# STM32MP23_CM33 register map
File version: 1.2
CPU: CM33 r0p1, little endian, MPU, FPU, vendor SysTick, 8 interrupt priority bits
Registers are 32-bit, read-write, reset 0x0 unless marked. A register's access mark holds for its fields unless they carry their own. Offsets are from the block's base; [hi:lo] are bit positions; {n}, {i} and the like mark numbered series; 'fields as' and 'values as' point back to an identical list.

## SERC — SERC register block
Base 0x44080000
Same registers: SERC_S 0x54080000
{0x0+4i} SERC_IER{i} (i=0..5) — SERC interrupt enable register {i}
  [31:0] PDRIE — Power-down or reset interrupt enable for peripheral y Sets the bit to unmask access to power-down or reset events from the peripheral y.
    0=power-down or reset access event from peripheral y does not generate an interrupt (masked); 1=power-down or reset access event from peripheral y generates an interrupt (unmasked)
{0x40+4i} SERC_ISR{i} ro (i=0..4) — SERC interrupt status register {i}
  [31:0] PDRS — Power-down or reset interrupt status for peripheral y The collector sets this bit when a bus_ilac is collected for peripheral y.
    0=no power-down or reset event recorded for this peripheral; 1=a power-down or reset access event has been reported from this peripheral
0x54 SERC_ISR5 ro — SERC interrupt status register 5
  [31:0] PDRS — Power-down or reset clear flag for peripheral y The collector sets this bit when a bus_ilac is collected for peripheral y.
    values as SERC_ISR0.PDRS
{0x80+4i} SERC_ICR{i} wo (i=0..5) — SERC interrupt clear register {i}
  [31:0] PDRC — Power-down or reset clear flag for peripheral y When set, this write-only bit clears the status flag of the illegal access event y set in SERC_ISR{i} register.
    0=PDRCy flag status is not affected; 1=PDRCy flag status is cleared in SERC_ISR{i} register
0x100 SERC_ENABLE
  [0] SERFEN — Enable the SERF framework. When the SERF is enabled, an access to a target under reset or clocked off is detected; a functional error response is given back on the IP bus, an illegal access is reported to the SERC, and an interrupt is fired according to the SERC registers configuration. When the SERF is disabled, an access to a target under reset or clocked off is not detected.
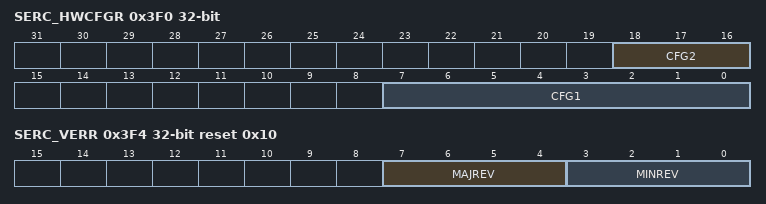
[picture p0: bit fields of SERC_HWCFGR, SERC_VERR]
0x3F0 SERC_HWCFGR ro (reset mask 0xFFF0FF00) — SERC hardware configuration register
  [18:16] CFG2 — NUM_RESYNC_FLOPS, number of resynchronization flops when receiving a bus_ilac information in the SERC clock domain.
  [7:0] CFG1 — NUM_ILAC, number of illegal accesses input pins configured for this instance of the collector.
0x3F4 SERC_VERR ro reset 0x10 — SERC version register
  [7:4] MAJREV — Major revision
  [3:0] MINREV — Minor revision
0x3F8 SERC_IPIDR ro reset 0x1001F0 — SERC identification register
  [31:0] ID — IP identification code
0x3FC SERC_SIDR ro reset 0xA3C5DD01 — SERC size identification register
  [31:0] SID — Size identification code (1 Kbyte)

## STGENR — System timer generator
Base 0x58070000
Same registers: STGENR_S 0x48070000
0x00 STGENR_CNTCVL ro — STGENR value lower register
  [31:0] CNTCVL_L_32 — current value of the timestamp counter (the lower 32 bits)
0x04 STGENR_CNTCVU ro — STGENR value upper register
  [31:0] CNTCVU_U_32 — current value of the timestamp counter (the upper 32 bits)
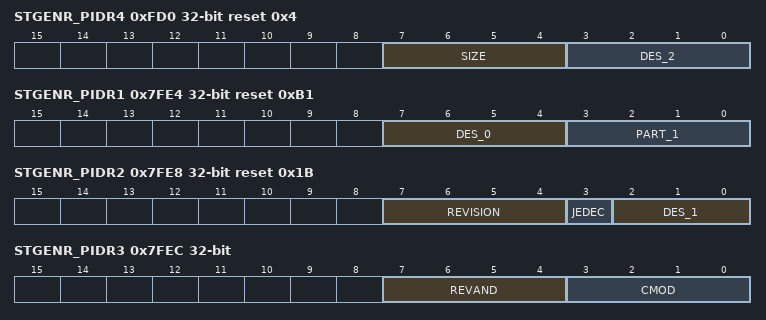
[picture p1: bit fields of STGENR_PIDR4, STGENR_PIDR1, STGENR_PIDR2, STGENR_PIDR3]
0xFD0 STGENR_PIDR4 ro reset 0x4 — STGENR peripheral ID4 register
  [7:4] SIZE — always 0b0000 Indicates that the device only occupies 4 Kbytes of memory.
  [3:0] DES_2 — part of designer identification Together STGEN_PIDR1.DES_0, STGEN_PIDR2.DES_1, and STGEN_PIDR4.DES_2 identify the designer of the component.
{0xFC0+4i} STGENR_PIDR{i} ro (i=5..7) — STGENR peripheral ID{i} register
  [31:0] PIDR{i} — peripheral ID{i}
0x7FE0 STGENR_PIDR0 ro reset 0x1 — STGENR peripheral ID0 register
  [7:0] PART_0 — bits[7:0] of the 12-bit part number of the component.
0x7FE4 STGENR_PIDR1 ro reset 0xB1 — STGENR peripheral ID1 register
  [7:4] DES_0 — part of designer identification Together STGEN_PIDR1.DES_0, STGEN_PIDR2.DES_1, and STGEN_PIDR4.DES_2 identify the designer of the component.
  [3:0] PART_1 — Bits[11:8] of the 12-bit part number of the component
0x7FE8 STGENR_PIDR2 ro reset 0x1B — STGENR peripheral ID2 register
  [7:4] REVISION — device revision number
  [3] JEDEC — always 1 Indicates that the JEDEC-assigned designer ID is used.
  [2:0] DES_1 — part of designer identification Together STGEN_PIDR1.DES_0, STGEN_PIDR2.DES_1, and STGEN_PIDR4.DES_2, identify the designer of the component.
0x7FEC STGENR_PIDR3 ro — STGENR peripheral ID3 register
  [7:4] REVAND — errata fix identification 0b0000 indicates there are no errata fixes to this component.
  [3:0] CMOD — customer modified Indicates whether the customer has modified the behavior of the component. In most cases, this field is 0b0000 (no modification done). Customers change this value when they make authorized modifications to this component.
0x7FF0 STGENR_CIDR0 ro reset 0xD — STGENR component ID0 register
  [7:0] PRMBL_0 — preamble 0 Contains bits[7:0] of the component identification code.
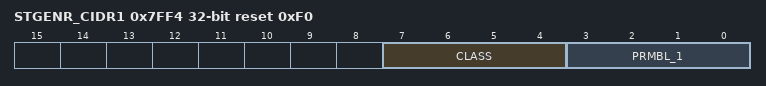
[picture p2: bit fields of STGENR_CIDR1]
0x7FF4 STGENR_CIDR1 ro reset 0xF0 — STGENR component ID1 register
  [7:4] CLASS — class of the component Contains bits[15:12] of the component identification code.
  [3:0] PRMBL_1 — preamble 1 Contains bits[11:8] of the component identification code.
0x7FF8 STGENR_CIDR2 ro reset 0x50 — STGENR component ID2 register
  [7:0] PRMBL_2 — preamble 2 Contains bits[23:16] of the component identification code.
0x7FFC STGENR_CIDR3 ro reset 0xB1 — STGENR component ID3 register
  [7:0] PRMBL_3 — preamble 3 Contains bits[31:24] of the component identification code.
